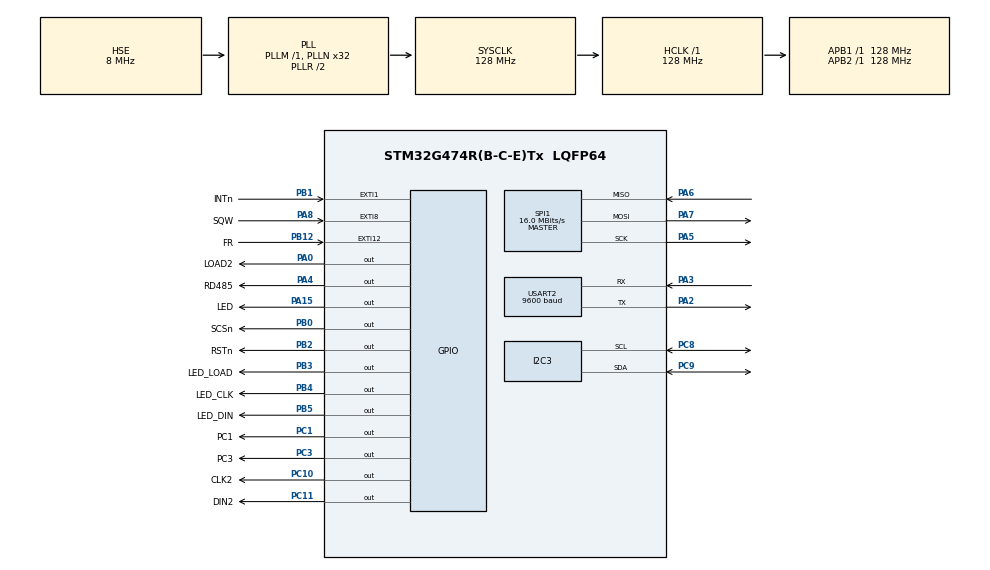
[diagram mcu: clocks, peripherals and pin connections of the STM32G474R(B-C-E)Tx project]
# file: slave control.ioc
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I2C3.Timing=0x20A0C4DF
Mcu.Family=STM32G4
Mcu.Name=STM32G474R(B-C-E)Tx
Mcu.Package=LQFP64
NVIC.EXTI15_10_IRQn=true\:0\:0\:false\:false\:true\:true\:true\:true
NVIC.EXTI1_IRQn=true\:0\:0\:false\:false\:true\:true\:true\:true
NVIC.EXTI9_5_IRQn=true\:0\:0\:false\:false\:true\:true\:true\:true
NVIC.PriorityGroup=NVIC_PRIORITYGROUP_4
NVIC.TIM1_UP_TIM16_IRQn=true\:0\:0\:false\:false\:true\:true\:true\:true
NVIC.TIM2_IRQn=true\:0\:0\:false\:false\:true\:true\:true\:true
NVIC.TIM3_IRQn=true\:0\:0\:false\:false\:true\:true\:true\:true
NVIC.TIM4_IRQn=true\:0\:0\:false\:false\:true\:true\:true\:true
NVIC.USART2_IRQn=true\:0\:0\:false\:false\:true\:true\:true\:true
PA0.GPIO_Label=LOAD2
PA0.GPIO_PuPd=GPIO_PULLUP
PA0.GPIO_Speed=GPIO_SPEED_FREQ_HIGH
PA0.PinState=GPIO_PIN_SET
PA0.Signal=GPIO_Output
PA15.GPIO_Label=LED
PA15.Signal=GPIO_Output
PA2.Mode=Asynchronous
PA2.Signal=USART2_TX
PA3.Mode=Asynchronous
PA3.Signal=USART2_RX
PA4.GPIO_Label=RD485
PA4.PinState=GPIO_PIN_SET
PA4.Signal=GPIO_Output
PA5.Mode=Full_Duplex_Master
PA5.Signal=SPI1_SCK
PA6.Mode=Full_Duplex_Master
PA6.Signal=SPI1_MISO
PA7.Mode=Full_Duplex_Master
PA7.Signal=SPI1_MOSI
PA8.GPIO_Label=SQW
PA8.GPIO_ModeDefaultEXTI=GPIO_MODE_IT_FALLING
PA8.GPIO_PuPd=GPIO_PULLUP
PA8.Signal=GPXTI8
PB0.GPIO_Label=SCSn
PB0.GPIO_PuPd=GPIO_PULLUP
PB0.Signal=GPIO_Output
PB1.GPIO_Label=INTn
PB1.GPIO_ModeDefaultEXTI=GPIO_MODE_IT_FALLING
PB1.GPIO_PuPd=GPIO_PULLUP
PB1.Signal=GPXTI1
PB12.GPIO_Label=FR
PB12.GPIO_ModeDefaultEXTI=GPIO_MODE_IT_FALLING
PB12.GPIO_PuPd=GPIO_PULLUP
PB12.Signal=GPXTI12
PB2.GPIO_Label=RSTn
PB2.GPIO_PuPd=GPIO_PULLUP
PB2.Signal=GPIO_Output
PB3.GPIO_Label=LED_LOAD
PB3.GPIO_PuPd=GPIO_PULLUP
PB3.GPIO_Speed=GPIO_SPEED_FREQ_VERY_HIGH
PB3.PinState=GPIO_PIN_SET
PB3.Signal=GPIO_Output
PB4.GPIO_Label=LED_CLK
PB4.GPIO_Speed=GPIO_SPEED_FREQ_VERY_HIGH
PB4.Signal=GPIO_Output
PB5.GPIO_Label=LED_DIN
PB5.GPIO_Speed=GPIO_SPEED_FREQ_VERY_HIGH
PB5.Signal=GPIO_Output
PC1.GPIO_Label=PC1
PC1.Signal=GPIO_Output
PC10.GPIO_Label=CLK2
PC10.GPIO_Speed=GPIO_SPEED_FREQ_HIGH
PC10.Signal=GPIO_Output
PC11.GPIO_Label=DIN2
PC11.GPIO_Speed=GPIO_SPEED_FREQ_HIGH
PC11.Signal=GPIO_Output
PC3.GPIO_Label=PC3
PC3.Signal=GPIO_Output
PC8.GPIO_Pu=GPIO_PULLUP
PC8.Mode=I2C
PC8.Signal=I2C3_SCL
PC9.GPIO_Pu=GPIO_PULLUP
PC9.Mode=I2C
PC9.Signal=I2C3_SDA
PF0-OSC_IN.Mode=HSE-External-Oscillator
PF0-OSC_IN.Signal=RCC_OSC_IN
PF1-OSC_OUT.Mode=HSE-External-Oscillator
PF1-OSC_OUT.Signal=RCC_OSC_OUT
ProjectManager.HeapSize=0x200
ProjectManager.StackSize=0x400
ProjectManager.TargetToolchain=MDK-ARM V5
RCC.ADC12Freq_Value=128000000
RCC.ADC345Freq_Value=128000000
RCC.AHBFreq_Value=128000000
RCC.APB1Freq_Value=128000000
RCC.APB1TimFreq_Value=128000000
RCC.APB2Freq_Value=128000000
RCC.APB2TimFreq_Value=128000000
RCC.CortexFreq_Value=128000000
RCC.EXTERNAL_CLOCK_VALUE=12288000
RCC.HCLKFreq_Value=128000000
RCC.HSE_VALUE=8000000
RCC.HSI48_VALUE=48000000
RCC.HSI_VALUE=16000000
RCC.LSE_VALUE=32768
RCC.PLLN=32
RCC.PLLSourceVirtual=RCC_PLLSOURCE_HSE
RCC.SYSCLKFreq_VALUE=128000000
RCC.SYSCLKSource=RCC_SYSCLKSOURCE_PLLCLK
RCC.USBFreq_Value=128000000
RCC.VCOOutputFreq_Value=256000000
SPI1.BaudRatePrescaler=SPI_BAUDRATEPRESCALER_8
SPI1.CLKPhase=SPI_PHASE_2EDGE
SPI1.CLKPolarity=SPI_POLARITY_HIGH
SPI1.CalculateBaudRate=16.0 MBits/s
SPI1.DataSize=SPI_DATASIZE_8BIT
SPI1.Direction=SPI_DIRECTION_2LINES
SPI1.Mode=SPI_MODE_MASTER
SPI1.VirtualType=VM_MASTER
TIM1.PeriodNoDither=9999
TIM1.Prescaler=12800-1
TIM2.PeriodNoDither=99999
TIM2.Prescaler=12800-1
TIM3.AutoReloadPreload=TIM_AUTORELOAD_PRELOAD_DISABLE
TIM3.PeriodNoDither=1000-1
TIM3.Prescaler=128-1
TIM4.PeriodNoDither=2000-1
TIM4.Prescaler=(128/2)-1
USART2.BaudRate=9600
USART2.VirtualMode-Asynchronous=VM_ASYNC
VP_IWDG_VS_IWDG.Mode=IWDG_Activate
VP_SYS_VS_DBSignals.Mode=DisableDeadBatterySignals
VP_TIM1_VS_ClockSourceINT.Mode=Internal
VP_TIM2_VS_ClockSourceINT.Mode=Internal
VP_TIM3_VS_ClockSourceINT.Mode=Internal
VP_TIM4_VS_ClockSourceINT.Mode=Internal
board=custom

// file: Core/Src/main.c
/* USER CODE BEGIN Header */
/**
  ******************************************************************************
  * @file           : main.c
  * @brief          : Main program body
  ******************************************************************************
  * @attention
  *
  * Copyright (c) 2022 STMicroelectronics.
  * All rights reserved.
  *
  * This software is licensed under terms that can be found in the LICENSE file
  * in the root directory of this software component.
  * If no LICENSE file comes with this software, it is provided AS-IS.
  *
  ******************************************************************************
  */
/* USER CODE END Header */
#include "main.h"

/* USER CODE BEGIN Includes */
#include "mydefines.h"
#include <time.h>
#include "stdio.h"
#include "wizchip_conf.h"
/* USER CODE END Includes */

/* USER CODE BEGIN PTD */
const time_t built_time = 1721202441;
uint8_t ntpTimeServer_ip[4] ={192,168,1,39};// NTP time server 139.199.215.251
uint8_t useDNS = 0;
//162.159.200.1
#ifdef SLAVE_CONSOLE
wiz_NetInfo myipWIZNETINFO = { .mac = {0x00, 0x08, 0xDC, 0x55, 0x00, 0x23},
															 .ip = {192, 168, 1, 98},
															 .sn = {255,255,255,0},
															 .gw = {192, 168, 1, 1},
															 .dns = {8,8,4,4},
															 .dhcp = NETINFO_STATIC };
#endif
#ifdef SLAVE_WALL
wiz_NetInfo myipWIZNETINFO = { .mac = {0x00, 0x08, 0xDC, 0x55, 0x00, 0x21},
															 .ip = {192, 168, 1, 100},
															 .sn = {255,255,255,0},
															 .gw = {192, 168, 1, 1},
															 .dns = {8,8,4,4},
															 .dhcp = NETINFO_STATIC };
#endif

#ifdef SLAVE_MATRIX
wiz_NetInfo myipWIZNETINFO = { .mac = {0x00, 0x08, 0xDC, 0x55, 0x00, 0x22},
															 .ip = {192, 168, 1, 96},
															 .sn = {255,255,255,0},
															 .gw = {0, 0, 0, 0},
															 .dns = {8,8,4,4},
															 .dhcp = NETINFO_STATIC };
#endif

/* USER CODE END PTD */

I2C_HandleTypeDef hi2c3;

IWDG_HandleTypeDef hiwdg;

SPI_HandleTypeDef hspi1;

TIM_HandleTypeDef htim1;
TIM_HandleTypeDef htim2;
TIM_HandleTypeDef htim3;
TIM_HandleTypeDef htim4;

UART_HandleTypeDef huart2;

void SystemClock_Config(void);
static void MX_GPIO_Init(void);
static void MX_SPI1_Init(void);
static void MX_TIM3_Init(void);
static void MX_USART2_UART_Init(void);
static void MX_I2C3_Init(void);
static void MX_TIM4_Init(void);
static void MX_IWDG_Init(void);
static void MX_TIM1_Init(void);
static void MX_TIM2_Init(void);

/* USER CODE BEGIN 0 */

time_t timenow ;
struct tm* timeinfo;
struct tm currtime;
uint8_t days ;
uint8_t months ;
uint8_t years ;
uint8_t hours ;
uint8_t minutes ;
uint8_t seconds ;
uint8_t server_hour, server_minute, server_second,server_day, server_month,server_year ;
//mui gio
uint8_t timeZone = 0;// timeZone = 0, gio UTC
// Buffer UART
uint8_t aRxBuffer[RXBUFFERSIZE];
uint8_t volatile waitForSetTime = 0;

/* USER CODE END 0 */

int main(void)
{

  /* MCU Configuration--------------------------------------------------------*/

  /* Reset of all peripherals, Initializes the Flash interface and the Systick. */
  HAL_Init();

  /* USER CODE BEGIN Init */

	//LOAD FS
	//config ...

  /* USER CODE END Init */

  /* Configure the system clock */
  SystemClock_Config();

  /* Initialize all configured peripherals */
  MX_GPIO_Init();
  MX_SPI1_Init();
  MX_TIM3_Init();
  MX_USART2_UART_Init();
  MX_I2C3_Init();
  MX_TIM4_Init();
  MX_IWDG_Init();
  MX_TIM1_Init();
  MX_TIM2_Init();
  /* USER CODE BEGIN 2 */
	HAL_TIM_Base_Start_IT(&htim1);
	HAL_TIM_Base_Start_IT(&htim2);
	HAL_TIM_Base_Start_IT(&htim3);
	HAL_TIM_Base_Start_IT(&htim4);

	HAL_GPIO_WritePin(LOAD2_GPIO_Port, LOAD2_Pin, GPIO_PIN_SET);
	HAL_GPIO_WritePin(LED_LOAD_GPIO_Port, LED_LOAD_Pin, GPIO_PIN_SET);

	HAL_GPIO_WritePin(RD485_GPIO_Port, RD485_Pin, GPIO_PIN_SET);

	slaveClockFucnsInit();
	#ifdef SLAVE_MATRIX
	HAL_GPIO_WritePin(GPIOC, GPIO_PIN_2|PC3_Pin, GPIO_PIN_SET);//Tat het den => dan dc ban tin
	#endif
	HAL_GPIO_WritePin(RD485_GPIO_Port, RD485_Pin, GPIO_PIN_RESET);

  /* USER CODE END 2 */

  /* Infinite loop */
  while (1)
  {

    /* USER CODE BEGIN 3 */
		HAL_IWDG_Refresh(&hiwdg);
		slaveClockRun();
  }
  /* USER CODE END 3 */
}

void SystemClock_Config(void)
{
  RCC_OscInitTypeDef RCC_OscInitStruct = {0};
  RCC_ClkInitTypeDef RCC_ClkInitStruct = {0};

  /** Configure the main internal regulator output voltage
  */
  HAL_PWREx_ControlVoltageScaling(PWR_REGULATOR_VOLTAGE_SCALE1);

  /** Initializes the RCC Oscillators according to the specified parameters
  * in the RCC_OscInitTypeDef structure.
  */
  RCC_OscInitStruct.OscillatorType = RCC_OSCILLATORTYPE_LSI|RCC_OSCILLATORTYPE_HSE;
  RCC_OscInitStruct.HSEState = RCC_HSE_ON;
  RCC_OscInitStruct.LSIState = RCC_LSI_ON;
  RCC_OscInitStruct.PLL.PLLState = RCC_PLL_ON;
  RCC_OscInitStruct.PLL.PLLSource = RCC_PLLSOURCE_HSE;
  RCC_OscInitStruct.PLL.PLLM = RCC_PLLM_DIV1;
  RCC_OscInitStruct.PLL.PLLN = 32;
  RCC_OscInitStruct.PLL.PLLP = RCC_PLLP_DIV2;
  RCC_OscInitStruct.PLL.PLLQ = RCC_PLLQ_DIV2;
  RCC_OscInitStruct.PLL.PLLR = RCC_PLLR_DIV2;
  if (HAL_RCC_OscConfig(&RCC_OscInitStruct) != HAL_OK)
  {
    Error_Handler();
  }

  /** Initializes the CPU, AHB and APB buses clocks
  */
  RCC_ClkInitStruct.ClockType = RCC_CLOCKTYPE_HCLK|RCC_CLOCKTYPE_SYSCLK
                              |RCC_CLOCKTYPE_PCLK1|RCC_CLOCKTYPE_PCLK2;
  RCC_ClkInitStruct.SYSCLKSource = RCC_SYSCLKSOURCE_PLLCLK;
  RCC_ClkInitStruct.AHBCLKDivider = RCC_SYSCLK_DIV1;
  RCC_ClkInitStruct.APB1CLKDivider = RCC_HCLK_DIV1;
  RCC_ClkInitStruct.APB2CLKDivider = RCC_HCLK_DIV1;

  if (HAL_RCC_ClockConfig(&RCC_ClkInitStruct, FLASH_LATENCY_4) != HAL_OK)
  {
    Error_Handler();
  }
}

static void MX_I2C3_Init(void)
{

  hi2c3.Instance = I2C3;
  hi2c3.Init.Timing = 0x20A0C4DF;
  hi2c3.Init.OwnAddress1 = 0;
  hi2c3.Init.AddressingMode = I2C_ADDRESSINGMODE_7BIT;
  hi2c3.Init.DualAddressMode = I2C_DUALADDRESS_DISABLE;
  hi2c3.Init.OwnAddress2 = 0;
  hi2c3.Init.OwnAddress2Masks = I2C_OA2_NOMASK;
  hi2c3.Init.GeneralCallMode = I2C_GENERALCALL_DISABLE;
  hi2c3.Init.NoStretchMode = I2C_NOSTRETCH_DISABLE;
  if (HAL_I2C_Init(&hi2c3) != HAL_OK)
  {
    Error_Handler();
  }

  /** Configure Analogue filter
  */
  if (HAL_I2CEx_ConfigAnalogFilter(&hi2c3, I2C_ANALOGFILTER_ENABLE) != HAL_OK)
  {
    Error_Handler();
  }

  /** Configure Digital filter
  */
  if (HAL_I2CEx_ConfigDigitalFilter(&hi2c3, 0) != HAL_OK)
  {
    Error_Handler();
  }

}

static void MX_IWDG_Init(void)
{

  hiwdg.Instance = IWDG;
  hiwdg.Init.Prescaler = IWDG_PRESCALER_128;
  hiwdg.Init.Window = 4095;
  hiwdg.Init.Reload = 4095;
  if (HAL_IWDG_Init(&hiwdg) != HAL_OK)
  {
    Error_Handler();
  }

}

static void MX_SPI1_Init(void)
{

  /* SPI1 parameter configuration*/
  hspi1.Instance = SPI1;
  hspi1.Init.Mode = SPI_MODE_MASTER;
  hspi1.Init.Direction = SPI_DIRECTION_2LINES;
  hspi1.Init.DataSize = SPI_DATASIZE_8BIT;
  hspi1.Init.CLKPolarity = SPI_POLARITY_HIGH;
  hspi1.Init.CLKPhase = SPI_PHASE_2EDGE;
  hspi1.Init.NSS = SPI_NSS_SOFT;
  hspi1.Init.BaudRatePrescaler = SPI_BAUDRATEPRESCALER_8;
  hspi1.Init.FirstBit = SPI_FIRSTBIT_MSB;
  hspi1.Init.TIMode = SPI_TIMODE_DISABLE;
  hspi1.Init.CRCCalculation = SPI_CRCCALCULATION_DISABLE;
  hspi1.Init.CRCPolynomial = 7;
  hspi1.Init.CRCLength = SPI_CRC_LENGTH_DATASIZE;
  hspi1.Init.NSSPMode = SPI_NSS_PULSE_DISABLE;
  if (HAL_SPI_Init(&hspi1) != HAL_OK)
  {
    Error_Handler();
  }

}

static void MX_TIM1_Init(void)
{

  TIM_ClockConfigTypeDef sClockSourceConfig = {0};
  TIM_MasterConfigTypeDef sMasterConfig = {0};

  htim1.Instance = TIM1;
  htim1.Init.Prescaler = 12800-1;
  htim1.Init.CounterMode = TIM_COUNTERMODE_UP;
  htim1.Init.Period = 9999;
  htim1.Init.ClockDivision = TIM_CLOCKDIVISION_DIV1;
  htim1.Init.RepetitionCounter = 0;
  htim1.Init.AutoReloadPreload = TIM_AUTORELOAD_PRELOAD_DISABLE;
  if (HAL_TIM_Base_Init(&htim1) != HAL_OK)
  {
    Error_Handler();
  }
  sClockSourceConfig.ClockSource = TIM_CLOCKSOURCE_INTERNAL;
  if (HAL_TIM_ConfigClockSource(&htim1, &sClockSourceConfig) != HAL_OK)
  {
    Error_Handler();
  }
  sMasterConfig.MasterOutputTrigger = TIM_TRGO_RESET;
  sMasterConfig.MasterOutputTrigger2 = TIM_TRGO2_RESET;
  sMasterConfig.MasterSlaveMode = TIM_MASTERSLAVEMODE_DISABLE;
  if (HAL_TIMEx_MasterConfigSynchronization(&htim1, &sMasterConfig) != HAL_OK)
  {
    Error_Handler();
  }

}

static void MX_TIM2_Init(void)
{

  TIM_ClockConfigTypeDef sClockSourceConfig = {0};
  TIM_MasterConfigTypeDef sMasterConfig = {0};

  htim2.Instance = TIM2;
  htim2.Init.Prescaler = 12800-1;
  htim2.Init.CounterMode = TIM_COUNTERMODE_UP;
  htim2.Init.Period = 99999;
  htim2.Init.ClockDivision = TIM_CLOCKDIVISION_DIV1;
  htim2.Init.AutoReloadPreload = TIM_AUTORELOAD_PRELOAD_DISABLE;
  if (HAL_TIM_Base_Init(&htim2) != HAL_OK)
  {
    Error_Handler();
  }
  sClockSourceConfig.ClockSource = TIM_CLOCKSOURCE_INTERNAL;
  if (HAL_TIM_ConfigClockSource(&htim2, &sClockSourceConfig) != HAL_OK)
  {
    Error_Handler();
  }
  sMasterConfig.MasterOutputTrigger = TIM_TRGO_RESET;
  sMasterConfig.MasterSlaveMode = TIM_MASTERSLAVEMODE_DISABLE;
  if (HAL_TIMEx_MasterConfigSynchronization(&htim2, &sMasterConfig) != HAL_OK)
  {
    Error_Handler();
  }

}

static void MX_TIM3_Init(void)
{

  TIM_ClockConfigTypeDef sClockSourceConfig = {0};
  TIM_MasterConfigTypeDef sMasterConfig = {0};

  htim3.Instance = TIM3;
  htim3.Init.Prescaler = 128-1;
  htim3.Init.CounterMode = TIM_COUNTERMODE_UP;
  htim3.Init.Period = 999;
  htim3.Init.ClockDivision = TIM_CLOCKDIVISION_DIV1;
  htim3.Init.AutoReloadPreload = TIM_AUTORELOAD_PRELOAD_DISABLE;
  if (HAL_TIM_Base_Init(&htim3) != HAL_OK)
  {
    Error_Handler();
  }
  sClockSourceConfig.ClockSource = TIM_CLOCKSOURCE_INTERNAL;
  if (HAL_TIM_ConfigClockSource(&htim3, &sClockSourceConfig) != HAL_OK)
  {
    Error_Handler();
  }
  sMasterConfig.MasterOutputTrigger = TIM_TRGO_RESET;
  sMasterConfig.MasterSlaveMode = TIM_MASTERSLAVEMODE_DISABLE;
  if (HAL_TIMEx_MasterConfigSynchronization(&htim3, &sMasterConfig) != HAL_OK)
  {
    Error_Handler();
  }

}

static void MX_TIM4_Init(void)
{

  TIM_ClockConfigTypeDef sClockSourceConfig = {0};
  TIM_MasterConfigTypeDef sMasterConfig = {0};

  htim4.Instance = TIM4;
  htim4.Init.Prescaler = 12800-1;
  htim4.Init.CounterMode = TIM_COUNTERMODE_UP;
  htim4.Init.Period = 19999;//2s
  htim4.Init.ClockDivision = TIM_CLOCKDIVISION_DIV1;
  htim4.Init.AutoReloadPreload = TIM_AUTORELOAD_PRELOAD_DISABLE;
  if (HAL_TIM_Base_Init(&htim4) != HAL_OK)
  {
    Error_Handler();
  }
  sClockSourceConfig.ClockSource = TIM_CLOCKSOURCE_INTERNAL;
  if (HAL_TIM_ConfigClockSource(&htim4, &sClockSourceConfig) != HAL_OK)
  {
    Error_Handler();
  }
  sMasterConfig.MasterOutputTrigger = TIM_TRGO_RESET;
  sMasterConfig.MasterSlaveMode = TIM_MASTERSLAVEMODE_DISABLE;
  if (HAL_TIMEx_MasterConfigSynchronization(&htim4, &sMasterConfig) != HAL_OK)
  {
    Error_Handler();
  }

}

static void MX_USART2_UART_Init(void)
{

  huart2.Instance = USART2;
  huart2.Init.BaudRate = 9600;
  huart2.Init.WordLength = UART_WORDLENGTH_8B;
  huart2.Init.StopBits = UART_STOPBITS_1;
  huart2.Init.Parity = UART_PARITY_NONE;
  huart2.Init.Mode = UART_MODE_TX_RX;
  huart2.Init.HwFlowCtl = UART_HWCONTROL_NONE;
  huart2.Init.OverSampling = UART_OVERSAMPLING_16;
  huart2.Init.OneBitSampling = UART_ONE_BIT_SAMPLE_DISABLE;
  huart2.Init.ClockPrescaler = UART_PRESCALER_DIV1;
  huart2.AdvancedInit.AdvFeatureInit = UART_ADVFEATURE_NO_INIT;
  if (HAL_UART_Init(&huart2) != HAL_OK)
  {
    Error_Handler();
  }
  if (HAL_UARTEx_SetTxFifoThreshold(&huart2, UART_TXFIFO_THRESHOLD_1_8) != HAL_OK)
  {
    Error_Handler();
  }
  if (HAL_UARTEx_SetRxFifoThreshold(&huart2, UART_RXFIFO_THRESHOLD_1_8) != HAL_OK)
  {
    Error_Handler();
  }
  if (HAL_UARTEx_DisableFifoMode(&huart2) != HAL_OK)
  {
    Error_Handler();
  }

}

static void MX_GPIO_Init(void)
{
  GPIO_InitTypeDef GPIO_InitStruct = {0};

  /* GPIO Ports Clock Enable */
  __HAL_RCC_GPIOF_CLK_ENABLE();
  __HAL_RCC_GPIOC_CLK_ENABLE();
  __HAL_RCC_GPIOA_CLK_ENABLE();
  __HAL_RCC_GPIOB_CLK_ENABLE();

  /*Configure GPIO pin Output Level */
  HAL_GPIO_WritePin(GPIOC, PC1_Pin|PC3_Pin|CLK2_Pin|DIN2_Pin, GPIO_PIN_RESET);

  /*Configure GPIO pin Output Level */
  HAL_GPIO_WritePin(GPIOA, LOAD2_Pin|RD485_Pin, GPIO_PIN_SET);

  /*Configure GPIO pin Output Level */
  HAL_GPIO_WritePin(GPIOB, SCSn_Pin|RSTn_Pin|LED_CLK_Pin|LED_DIN_Pin, GPIO_PIN_RESET);

  /*Configure GPIO pin Output Level */
  HAL_GPIO_WritePin(LED_GPIO_Port, LED_Pin, GPIO_PIN_RESET);

  /*Configure GPIO pin Output Level */
  HAL_GPIO_WritePin(LED_LOAD_GPIO_Port, LED_LOAD_Pin, GPIO_PIN_SET);

  /*Configure GPIO pins : PC1_Pin PC3_Pin */
  GPIO_InitStruct.Pin = PC1_Pin|GPIO_PIN_2|PC3_Pin;
  GPIO_InitStruct.Mode = GPIO_MODE_OUTPUT_PP;
  GPIO_InitStruct.Pull = GPIO_NOPULL;
  GPIO_InitStruct.Speed = GPIO_SPEED_FREQ_VERY_HIGH;
  HAL_GPIO_Init(GPIOC, &GPIO_InitStruct);

  /*Configure GPIO pin : LOAD2_Pin */
  GPIO_InitStruct.Pin = LOAD2_Pin;
  GPIO_InitStruct.Mode = GPIO_MODE_OUTPUT_PP;
  GPIO_InitStruct.Pull = GPIO_PULLUP;
  GPIO_InitStruct.Speed = GPIO_SPEED_FREQ_VERY_HIGH;
  HAL_GPIO_Init(LOAD2_GPIO_Port, &GPIO_InitStruct);

  /*Configure GPIO pins : RD485_Pin LED_Pin */
  GPIO_InitStruct.Pin = RD485_Pin|LED_Pin;
  GPIO_InitStruct.Mode = GPIO_MODE_OUTPUT_PP;
  GPIO_InitStruct.Pull = GPIO_PULLUP;
  GPIO_InitStruct.Speed = GPIO_SPEED_FREQ_VERY_HIGH;
  HAL_GPIO_Init(GPIOA, &GPIO_InitStruct);

  /*Configure GPIO pins : SCSn_Pin RSTn_Pin */
  GPIO_InitStruct.Pin = SCSn_Pin|RSTn_Pin;
  GPIO_InitStruct.Mode = GPIO_MODE_OUTPUT_PP;
  GPIO_InitStruct.Pull = GPIO_PULLUP;
  GPIO_InitStruct.Speed = GPIO_SPEED_FREQ_VERY_HIGH;
  HAL_GPIO_Init(GPIOB, &GPIO_InitStruct);

  /*Configure GPIO pins : INTn_Pin FR_Pin */
  GPIO_InitStruct.Pin = INTn_Pin|FR_Pin;
  GPIO_InitStruct.Mode = GPIO_MODE_IT_FALLING;
  GPIO_InitStruct.Pull = GPIO_PULLUP;
  HAL_GPIO_Init(GPIOB, &GPIO_InitStruct);

  /*Configure GPIO pin : SQW_Pin */
  GPIO_InitStruct.Pin = SQW_Pin;
  GPIO_InitStruct.Mode = GPIO_MODE_IT_FALLING;
  GPIO_InitStruct.Pull = GPIO_PULLUP;
  HAL_GPIO_Init(SQW_GPIO_Port, &GPIO_InitStruct);

  /*Configure GPIO pins : CLK2_Pin DIN2_Pin */
  GPIO_InitStruct.Pin = CLK2_Pin|DIN2_Pin;
  GPIO_InitStruct.Mode = GPIO_MODE_OUTPUT_PP;
  GPIO_InitStruct.Pull = GPIO_NOPULL;
  GPIO_InitStruct.Speed = GPIO_SPEED_FREQ_VERY_HIGH;
  HAL_GPIO_Init(GPIOC, &GPIO_InitStruct);

  /*Configure GPIO pin : LED_LOAD_Pin */
  GPIO_InitStruct.Pin = LED_LOAD_Pin;
  GPIO_InitStruct.Mode = GPIO_MODE_OUTPUT_PP;
  GPIO_InitStruct.Pull = GPIO_PULLUP;
  GPIO_InitStruct.Speed = GPIO_SPEED_FREQ_VERY_HIGH;
  HAL_GPIO_Init(LED_LOAD_GPIO_Port, &GPIO_InitStruct);

  /*Configure GPIO pins : LED_CLK_Pin LED_DIN_Pin */
  GPIO_InitStruct.Pin = LED_CLK_Pin|LED_DIN_Pin;
  GPIO_InitStruct.Mode = GPIO_MODE_OUTPUT_PP;
  GPIO_InitStruct.Pull = GPIO_PULLUP;
  GPIO_InitStruct.Speed = GPIO_SPEED_FREQ_VERY_HIGH;
  HAL_GPIO_Init(GPIOB, &GPIO_InitStruct);

  /* EXTI interrupt init*/
  HAL_NVIC_SetPriority(EXTI1_IRQn, 0, 0);
  HAL_NVIC_EnableIRQ(EXTI1_IRQn);

  HAL_NVIC_SetPriority(EXTI9_5_IRQn, 0, 0);
  HAL_NVIC_EnableIRQ(EXTI9_5_IRQn);

  HAL_NVIC_SetPriority(EXTI15_10_IRQn, 0, 0);
  HAL_NVIC_EnableIRQ(EXTI15_10_IRQn);

}

/* USER CODE BEGIN 4 */
#ifdef __GNUC__
  /* With GCC/RAISONANCE, small printf (option LD Linker->Libraries->Small printf
     set to 'Yes') calls __io_putchar() */
  #define PUTCHAR_PROTOTYPE int __io_putchar(int ch)
#else
  #define PUTCHAR_PROTOTYPE int fputc(int ch, FILE *f)
#endif /* __GNUC__ */

/**
  * @brief  Retargets the C library printf function to the USART.
  * @param  None
  * @retval None
  */
PUTCHAR_PROTOTYPE
{
	/* Place your implementation of fputc here */
	/* e.g. write a character to the USART */
	HAL_UART_Transmit(&huart2, (uint8_t *)&ch, 1, 100);
	return ch;
}
/* USER CODE END 4 */

void Error_Handler(void)
{
  __disable_irq();
  while (1)
  {
  }
}
